# haltium_celldsp register map
Vendor: Nordic Semiconductor; Series: nRFHaltium; File version: 1
Registers are 32-bit, read-write, reset 0x0 unless marked. A register's access mark holds for its fields unless they carry their own. Offsets are from the block's base; [hi:lo] are bit positions; lines under a group give offsets from that group; {n}, {i} and the like mark numbered series; 'fields as' and 'values as' point back to an identical list.

## DSPCTRL — DSP control
Base 0x45014000
0x400 CPUID ro reset 0x5 — CPU domain ID
  [3:0] CPUID
0x404 ENABLEIRQIPCBLOCKING — ENABLEIRQIPCBLOCKING should be enabled before DSP starts its shutdown or deepsleep routine. Register is automatically cleared when DSP wakes up. ENABLEIRQIPCBLOCKING blocks the IPC interrupt wake-up mechanism and the IRQ propagating to DSP interrupt input. If the IPC interrupt is not blocked, DSP can enter to unknown state, if IPC IRQ occurs during deepsleep or shutdown sequence.
  [0] ENABLEIRQIPCBLOCKING — Enable for blocking the IPC interrupt wake-up mechanism
    0=Disabled (Blocking disabled); 1=Enabled (Blocking enabled)
0x408 ENABLEFORCEOFF — Control for forcing off the DSP clock requesting
  [0] ENABLEFORCEOFF
    0=Disabled (DSP clock request force off disabled); 1=Enabled (DSP clock request force off enabled)
0x40C ENABLEDEEPSLEEP — Enable DSP deepsleep. Must be high before DSP enters deepsleep and must be low before entering to shutdown.
  [0] ENABLEDEEPSLEEP — Enable DSP deepsleep
    0=Disabled (Deep sleep disabled); 1=Enabled (Deep sleep enabled)
{0x410+4i} MASTERPRIORITY[{i}] (i=0..10) reset 0xFFFFFFFF — Description collection: Control priority for AXI master connected to the local AXI bus matrix. NOTE: actual reset values vary across the register array.
  [3:0] PRIORITY — Master n priority level
{0x43C+4i} SLAVEPRIORITY[{i}] (i=0..6) — Description collection: Control priority for AXI slaves connected to the local AXI bus matrix
  [2:0] PRIORITY — Slave n priority level

## PCGCM0 — PCGC Master 0
Base 0x45015000
Same registers: PCGCM1 0x45023000
{0xE0+4i} SETPWRCONTHRESHOLDBASE[{i}] (i=0..2) ro — Description collection: Set power consumption threshold base for power source / regulator n
  [3:0] SETPWRCONTHRESHOLDBASE
{0x100+4i} SETPOWERCONSUMPTIONBASE[{i}] (i=0..1) ro — Description collection: Set power consumption base for power/clock pair n
  [3:0] POWERREQUIREMENT
0xC00 UNLOCKBACKDOORS ro
  [15:0] UNLOCKBACKDOORS — Write: 0x00009375 to lock/unlock backdoors Read: 0x00000001 if backdoors is enabled Read: 0x00000000 if backdoors is disabled
0xC04 ENABLEPOWERREGFORCE ro
  [2:0] ENABLEPOWERREGFORCE
0xC08 POWERREGFORCE ro — Force reg
  [2:0] POWERREGFORCEREG
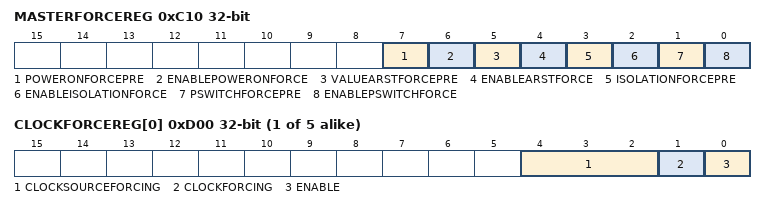
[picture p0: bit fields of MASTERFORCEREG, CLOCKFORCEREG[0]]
0xC10 MASTERFORCEREG ro — Force reg
  [7] POWERONFORCEPRE, [6] ENABLEPOWERONFORCE, [5] VALUEARSTFORCEPRE, [4] ENABLEARSTFORCE, [3] ISOLATIONFORCEPRE, [2] ENABLEISOLATIONFORCE, [1] PSWITCHFORCEPRE, [0] ENABLEPSWITCHFORCE
{0xD00+4i} CLOCKFORCEREG[{i}] (i=0..4) ro — Description collection: Force clock n
  [4:2] CLOCKSOURCEFORCING
  [1] CLOCKFORCING
  [0] ENABLE — Enable clock forcing

## DPPIC — Distributed programmable peripheral interconnect controller 0
Base 0x45021000
Same registers: GLOBAL_DPPIC120 0x4F8E1000, GLOBAL_DPPIC130 0x4F922000, GLOBAL_DPPIC131 0x4F981000, GLOBAL_DPPIC132 0x4F991000, GLOBAL_DPPIC133 0x4F9A1000, GLOBAL_DPPIC134 0x4F9B1000, GLOBAL_DPPIC135 0x4F9C1000, GLOBAL_DPPIC136 0x4F9D1000
{0x0+8i} TASKS_CHG[{i}] (i=0..5) group — Channel group tasks
  0x00 EN wo — Description cluster: Enable channel group n
    [0] EN — Enable channel group n
      1=Trigger task
  0x04 DIS wo — Description cluster: Disable channel group n
    [0] DIS — Disable channel group n
      1=Trigger task
{0x80+8i} SUBSCRIBE_CHG[{i}] (i=0..5) group — Subscribe configuration for tasks
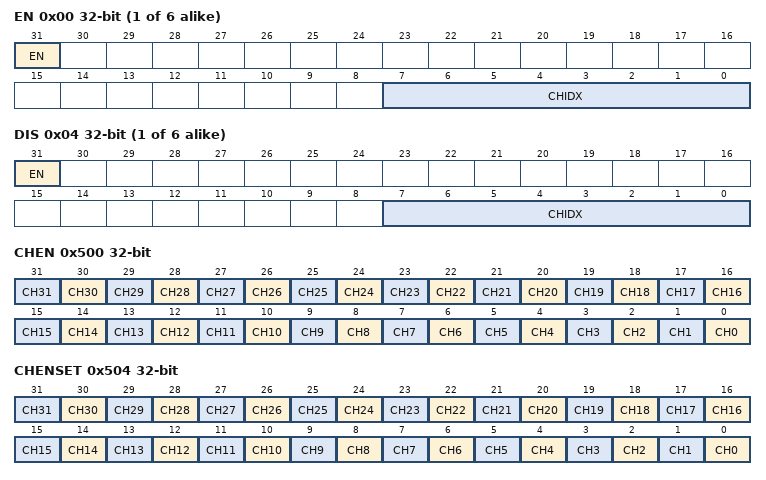
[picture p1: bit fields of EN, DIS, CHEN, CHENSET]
  0x00 EN — Description cluster: Subscribe configuration for task CHG[n].EN
    [31] EN
      0=Disabled (Disable subscription); 1=Enabled (Enable subscription)
    [7:0] CHIDX — DPPI channel that task CHG[n].EN will subscribe to
  0x04 DIS — Description cluster: Subscribe configuration for task CHG[n].DIS
    [31] EN
      values as SUBSCRIBE_CHG[0].EN.EN
    [7:0] CHIDX — DPPI channel that task CHG[n].DIS will subscribe to
0x500 CHEN — Channel enable register
  [all] fields
    0=Disabled (Disable channel); 1=Enabled (Enable channel)
  [n] CH{n} (n=0..31) — Enable or disable channel {n}
0x504 CHENSET write-1-sets — Channel enable set register
  [all] fields
    on read: 0=Disabled (Read: Channel disabled); 1=Enabled (Read: Channel enabled) | on write: 1=Set (Write: Enable channel)
  [n] CH{n} (n=0..31) — Channel {n} enable set register. Writing 0 has no effect.
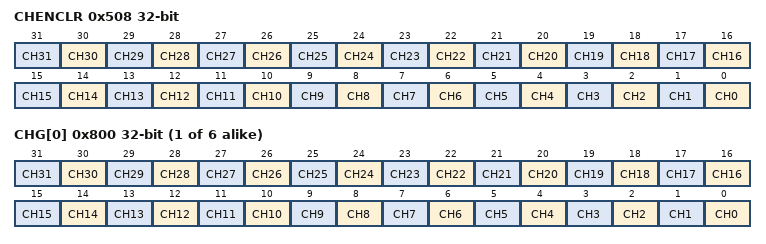
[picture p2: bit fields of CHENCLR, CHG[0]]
0x508 CHENCLR write-1-clears — Channel enable clear register
  [all] fields
    on read: 0=Disabled (Read: Channel disabled); 1=Enabled (Read: Channel enabled) | on write: 1=Clear (Write: Disable channel)
  [n] CH{n} (n=0..31) — Channel {n} enable clear register. Writing 0 has no effect.
{0x800+4i} CHG[{i}] (i=0..5) — Description collection: Channel group n Note: Writes to this register are ignored if either SUBSCRIBE_CHG[n].EN or SUBSCRIBE_CHG[n].DIS is enabled
  [all] fields
    0=Excluded; 1=Included
  [n] CH{n} (n=0..31) — Include or exclude channel {n}
